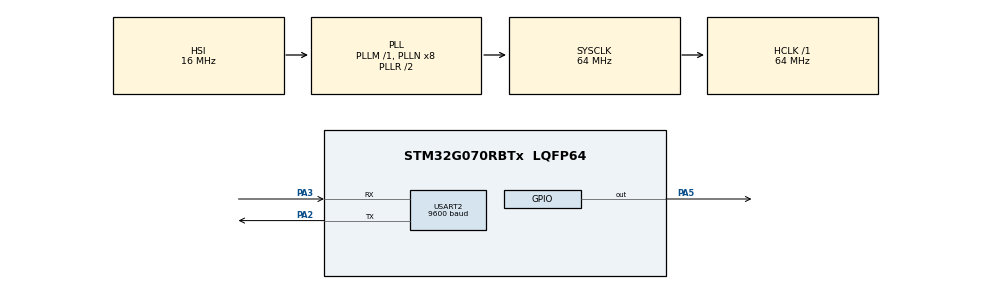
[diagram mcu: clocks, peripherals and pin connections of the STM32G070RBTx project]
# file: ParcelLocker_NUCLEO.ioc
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Mcu.Family=STM32G0
RCC.CortexFreq_Value=64000000
Dma.USART2_TX.0.MemInc=DMA_MINC_ENABLE
Dma.USART2_TX.0.PeriphDataAlignment=DMA_PDATAALIGN_BYTE
RCC.EXTERNAL_CLOCK_VALUE=48000
Dma.USART2_TX.0.EventEnable=DISABLE
NVIC.USART2_IRQn=true\:0\:0\:false\:false\:true\:true\:true
USART2.BaudRate=9600
RCC.SYSCLKSource=RCC_SYSCLKSOURCE_PLLCLK
ProjectManager.StackSize=0x400
PA3.Mode=Asynchronous
Dma.USART2_TX.0.Priority=DMA_PRIORITY_LOW
ProjectManager.TargetToolchain=STM32CubeIDE
RCC.HCLKFreq_Value=64000000
RCC.LSE_VALUE=32768
RCC.AHBFreq_Value=64000000
PA5.Signal=GPIO_Output
RCC.HSE_VALUE=8000000
board=custom
Dma.USART2_TX.0.SyncSignalID=NONE
USART2.VirtualMode-Asynchronous=VM_ASYNC
RCC.VCOOutputFreq_Value=128000000
Dma.USART2_TX.0.Polarity=HAL_DMAMUX_REQ_GEN_RISING
RCC.ADCFreq_Value=64000000
VP_SYS_VS_DBSignals.Mode=DisableDeadBatterySignals
Dma.USART2_TX.0.MemDataAlignment=DMA_MDATAALIGN_BYTE
Dma.USART2_TX.0.Direction=DMA_MEMORY_TO_PERIPH
Mcu.Name=STM32G070RBTx
Dma.USART2_TX.0.Instance=DMA1_Channel1
PA2.Signal=USART2_TX
RCC.SYSCLKFreq_VALUE=64000000
Mcu.Package=LQFP64
Dma.USART2_TX.0.SyncRequestNumber=1
Dma.USART2_TX.0.PeriphInc=DMA_PINC_DISABLE
Dma.USART2_TX.0.SignalID=NONE
ProjectManager.HeapSize=0x200
Dma.USART2_TX.0.RequestNumber=1
RCC.HSI_VALUE=16000000
Dma.USART2_TX.0.Mode=DMA_NORMAL
PA2.Mode=Asynchronous
Dma.USART2_TX.0.SyncPolarity=HAL_DMAMUX_SYNC_NO_EVENT
NVIC.DMA1_Channel1_IRQn=true\:0\:0\:false\:false\:true\:false\:true
Dma.Request0=USART2_TX
Dma.USART2_TX.0.SyncEnable=DISABLE
PA3.Signal=USART2_RX

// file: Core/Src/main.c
/* USER CODE BEGIN Header */
/**
  ******************************************************************************
  * @file           : main.c
  * @brief          : Main program body
  ******************************************************************************
  * @attention
  *
  * <h2><center>&copy; Copyright (c) 2021 STMicroelectronics.
  * All rights reserved.</center></h2>
  *
  * This software component is licensed by ST under BSD 3-Clause license,
  * the "License"; You may not use this file except in compliance with the
  * License. You may obtain a copy of the License at:
  *                        opensource.org/licenses/BSD-3-Clause
  *
  ******************************************************************************
  */
/* USER CODE END Header */
#include "main.h"

UART_HandleTypeDef huart2;
DMA_HandleTypeDef hdma_usart2_tx;

void SystemClock_Config(void);
static void MX_GPIO_Init(void);
static void MX_DMA_Init(void);
static void MX_USART2_UART_Init(void);

/* USER CODE BEGIN 0 */

/**
 * @brief Test callback function which is call when some box need to open/close
 *
 * @param [in] u8_box	This parameter is pointer to data in parcel_locker module.
 * 						If there by change it also by change in module.
 *
 */
void v_main_open_box(uint8_t u8_box[PRCLCR_CAINET_NUM][PRCLCR_NUM_OF_BOX_STATUS])
{
	/* This is local copy of box_number data store in parcel_locker module.
	 * It should by change without any effect to parcel_locker module.*/
	uint8_t u8_my_box[PRCLCR_CAINET_NUM][PRCLCR_NUM_OF_BOX_STATUS];
	xv_prclcr_get_box_status(u8_my_box);
}

/* USER CODE END 0 */

int main(void)
{

  /* MCU Configuration--------------------------------------------------------*/

  /* Reset of all peripherals, Initializes the Flash interface and the Systick. */
  HAL_Init();

  /* Configure the system clock */
  SystemClock_Config();

  /* Initialize all configured peripherals */
  MX_GPIO_Init();
  MX_DMA_Init();
  MX_USART2_UART_Init();
  /* USER CODE BEGIN 2 */

  __HAL_UART_ENABLE_IT(&huart2, UART_IT_RXNE);
  __enable_irq();

  /* USER CODE END 2 */

  /* Infinite loop */
  while (1)
  {

	/* 1 sec led light if some data are received.
	 * It is not part of Assignment. */
//	uint8_t i;
//	for(i = 0; i < 10; i++) {
//		HAL_GPIO_TogglePin(GPIOA, GPIO_PIN_5);
//		HAL_Delay(100);
//	}

	/* Suspend Sys Tick and go to sleep mode. */
	HAL_SuspendTick();
	HAL_PWR_EnterSLEEPMode(PWR_MAINREGULATOR_ON, PWR_SLEEPENTRY_WFI);
	HAL_ResumeTick();

  }
}

void SystemClock_Config(void)
{
  RCC_OscInitTypeDef RCC_OscInitStruct = {0};
  RCC_ClkInitTypeDef RCC_ClkInitStruct = {0};
  RCC_PeriphCLKInitTypeDef PeriphClkInit = {0};

  /** Configure the main internal regulator output voltage
  */
  HAL_PWREx_ControlVoltageScaling(PWR_REGULATOR_VOLTAGE_SCALE1);
  /** Initializes the RCC Oscillators according to the specified parameters
  * in the RCC_OscInitTypeDef structure.
  */
  RCC_OscInitStruct.OscillatorType = RCC_OSCILLATORTYPE_HSI;
  RCC_OscInitStruct.HSIState = RCC_HSI_ON;
  RCC_OscInitStruct.HSIDiv = RCC_HSI_DIV1;
  RCC_OscInitStruct.HSICalibrationValue = RCC_HSICALIBRATION_DEFAULT;
  RCC_OscInitStruct.PLL.PLLState = RCC_PLL_ON;
  RCC_OscInitStruct.PLL.PLLSource = RCC_PLLSOURCE_HSI;
  RCC_OscInitStruct.PLL.PLLM = RCC_PLLM_DIV1;
  RCC_OscInitStruct.PLL.PLLN = 8;
  RCC_OscInitStruct.PLL.PLLP = RCC_PLLP_DIV2;
  RCC_OscInitStruct.PLL.PLLR = RCC_PLLR_DIV2;
  if (HAL_RCC_OscConfig(&RCC_OscInitStruct) != HAL_OK)
  {
    Error_Handler();
  }
  /** Initializes the CPU, AHB and APB buses clocks
  */
  RCC_ClkInitStruct.ClockType = RCC_CLOCKTYPE_HCLK|RCC_CLOCKTYPE_SYSCLK
                              |RCC_CLOCKTYPE_PCLK1;
  RCC_ClkInitStruct.SYSCLKSource = RCC_SYSCLKSOURCE_PLLCLK;
  RCC_ClkInitStruct.AHBCLKDivider = RCC_SYSCLK_DIV1;
  RCC_ClkInitStruct.APB1CLKDivider = RCC_HCLK_DIV1;

  if (HAL_RCC_ClockConfig(&RCC_ClkInitStruct, FLASH_LATENCY_2) != HAL_OK)
  {
    Error_Handler();
  }
  /** Initializes the peripherals clocks
  */
  PeriphClkInit.PeriphClockSelection = RCC_PERIPHCLK_USART2;
  PeriphClkInit.Usart2ClockSelection = RCC_USART2CLKSOURCE_PCLK1;
  if (HAL_RCCEx_PeriphCLKConfig(&PeriphClkInit) != HAL_OK)
  {
    Error_Handler();
  }
}

static void MX_USART2_UART_Init(void)
{

  huart2.Instance = USART2;
  huart2.Init.BaudRate = 9600;
  huart2.Init.WordLength = UART_WORDLENGTH_8B;
  huart2.Init.StopBits = UART_STOPBITS_1;
  huart2.Init.Parity = UART_PARITY_NONE;
  huart2.Init.Mode = UART_MODE_TX_RX;
  huart2.Init.HwFlowCtl = UART_HWCONTROL_NONE;
  huart2.Init.OverSampling = UART_OVERSAMPLING_16;
  huart2.Init.OneBitSampling = UART_ONE_BIT_SAMPLE_DISABLE;
  huart2.Init.ClockPrescaler = UART_PRESCALER_DIV1;
  huart2.AdvancedInit.AdvFeatureInit = UART_ADVFEATURE_NO_INIT;
  if (HAL_UART_Init(&huart2) != HAL_OK)
  {
    Error_Handler();
  }
  if (HAL_UARTEx_SetTxFifoThreshold(&huart2, UART_TXFIFO_THRESHOLD_1_8) != HAL_OK)
  {
    Error_Handler();
  }
  if (HAL_UARTEx_SetRxFifoThreshold(&huart2, UART_RXFIFO_THRESHOLD_1_8) != HAL_OK)
  {
    Error_Handler();
  }
  if (HAL_UARTEx_DisableFifoMode(&huart2) != HAL_OK)
  {
    Error_Handler();
  }
  /* USER CODE BEGIN USART2_Init 2 */
  huart2.RxISR = xv_prclcr_uart_rx_callback;
  /* USER CODE END USART2_Init 2 */

}

static void MX_DMA_Init(void)
{

  /* DMA controller clock enable */
  __HAL_RCC_DMA1_CLK_ENABLE();

  /* DMA interrupt init */
  /* DMA1_Channel1_IRQn interrupt configuration */
  HAL_NVIC_SetPriority(DMA1_Channel1_IRQn, 0, 0);
  HAL_NVIC_EnableIRQ(DMA1_Channel1_IRQn);

}

static void MX_GPIO_Init(void)
{
  GPIO_InitTypeDef GPIO_InitStruct = {0};

  /* GPIO Ports Clock Enable */
  __HAL_RCC_GPIOA_CLK_ENABLE();

  /*Configure GPIO pin Output Level */
  HAL_GPIO_WritePin(GPIOA, GPIO_PIN_5, GPIO_PIN_RESET);

  /*Configure GPIO pin : PA5 */
  GPIO_InitStruct.Pin = GPIO_PIN_5;
  GPIO_InitStruct.Mode = GPIO_MODE_OUTPUT_PP;
  GPIO_InitStruct.Pull = GPIO_NOPULL;
  GPIO_InitStruct.Speed = GPIO_SPEED_FREQ_LOW;
  HAL_GPIO_Init(GPIOA, &GPIO_InitStruct);

}

void Error_Handler(void)
{
  __disable_irq();
  while (1)
  {
  }
}

/************************ (C) COPYRIGHT STMicroelectronics *****END OF FILE****/
